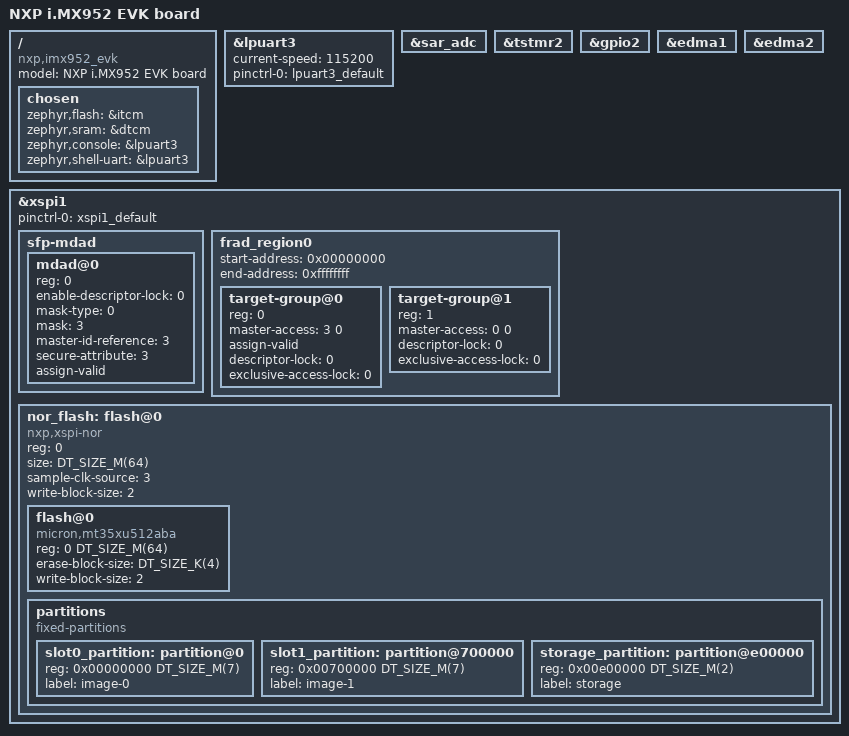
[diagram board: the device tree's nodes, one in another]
/*
 * SPDX-FileCopyrightText: Copyright 2026 NXP
 *
 * SPDX-License-Identifier: Apache-2.0
 */

/dts-v1/;

#include <nxp/imx/nxp_imx952_m7.dtsi>
#include "imx952_evk-pinctrl.dtsi"
#include <dt-bindings/mipi_dsi/mipi_dsi.h>

/ {
	compatible = "nxp,imx952_evk";
	model = "NXP i.MX952 EVK board";

	chosen {
		/* TCM */
		zephyr,flash = &itcm;
		zephyr,sram = &dtcm;

		zephyr,console = &lpuart3;
		zephyr,shell-uart = &lpuart3;
	};
};

&lpuart3 {
	current-speed = <115200>;
	pinctrl-0 = <&lpuart3_default>;
	pinctrl-names = "default";
	status = "okay";
};

&sar_adc {
	status = "okay";
};

&tstmr2 {
	status = "okay";
};

&gpio2 {
	status = "okay";
};

&edma1 {
	status = "okay";
};

&edma2 {
	status = "okay";
};

&xspi1 {
	pinctrl-0 = <&xspi1_default>;
	pinctrl-names = "default";
	status = "okay";

	/*
	 * Secure Flash Protection (SFP) MDAD configuration.
	 * i.MX952 CM7: SOC_CPU_DOMAIN_ID = 3.
	 * Property names / enums per dts/bindings/xspi/nxp,xspi.yaml.
	 *
	 * MDAD - first-level: secure attribute + master ID check.
	 * The sfp-mdad container holds one mdad@N child per target group; each
	 * child's unit-address (reg) is the tgMdad[] array subscript, matching
	 * the target-group@N style used by the FRAD regions.
	 */
	sfp-mdad {
		#address-cells = <1>;
		#size-cells = <0>;

		/* Target group 0 */
		mdad@0 {
			reg = <0>;
			enable-descriptor-lock = <0>;    /* descriptor lock disabled */
			mask-type = <0>;                 /* 0 = AND (kXSPI_MdadMaskTypeAnd) */
			mask = <3>;                      /* SOC_CPU_DOMAIN_ID */
			master-id-reference = <3>;       /* SOC_CPU_DOMAIN_ID */
			secure-attribute = <3>;          /* 3 = NonsecureSecureBoth */
			assign-valid;                    /* assignIsValid = true (TG0MDAD.VLD) */
		};
	};

	/*
	 * Secure Flash Protection (SFP) MDAD/FRAD configuration.
	 * Mirrors the MCUXpresso SDK cm7 xspi example.
	 * i.MX952 CM7: SOC_CPU_DOMAIN_ID = 3.
	 * Property names / enums per dts/bindings/xspi/nxp,xspi.yaml.
	 */

	/*
	 * FRAD - Region 0 (second-level: address-range access control).
	 * Per-target-group configuration: each target-group@N child maps to
	 * tgConfig[N], using its unit-address (reg) as the target-group index.
	 * The master-access array carries one access-permission entry per master
	 * (tgMasterAccess[]). Only target group 0, master 0 (domain 3) is granted
	 * access here.
	 */

	frad_region0 {
		start-address = <0x00000000>;
		end-address = <0xffffffff>;
		#address-cells = <1>;
		#size-cells = <0>;

		/* Target group 0: master0 = domain 3, master1 = 0 */
		target-group@0 {
			reg = <0>;
			master-access = <3 0>;
			assign-valid;
			descriptor-lock = <0>;
			exclusive-access-lock = <0>;
		};

		/* Target group 1 (unused) */
		target-group@1 {
			reg = <1>;
			master-access = <0 0>;
			descriptor-lock = <0>;
			exclusive-access-lock = <0>;
		};
	};

	nor_flash: flash@0 {
		compatible = "nxp,xspi-nor";
		reg = <0>;
		/* Micron MT35XU512ABA: 512 Mbit = 64 MByte */
		size = <DT_SIZE_M(64)>;

		sample-clk-source = <3>;
		write-block-size = <2>;
		#address-cells = <1>;
		#size-cells = <1>;

		flash@0 {
			compatible = "micron,mt35xu512aba", "soc-nv-flash";
			reg = <0 DT_SIZE_M(64)>;
			erase-block-size = <DT_SIZE_K(4)>;
			write-block-size = <2>;
		};

		partitions {
			compatible = "fixed-partitions";
			#address-cells = <1>;
			#size-cells = <1>;

			slot0_partition: partition@0 {
				reg = <0x00000000 DT_SIZE_M(7)>;
				label = "image-0";
			};

			slot1_partition: partition@700000 {
				reg = <0x00700000 DT_SIZE_M(7)>;
				label = "image-1";
			};

			storage_partition: partition@e00000 {
				reg = <0x00e00000 DT_SIZE_M(2)>;
				label = "storage";
			};
		};
	};
};
